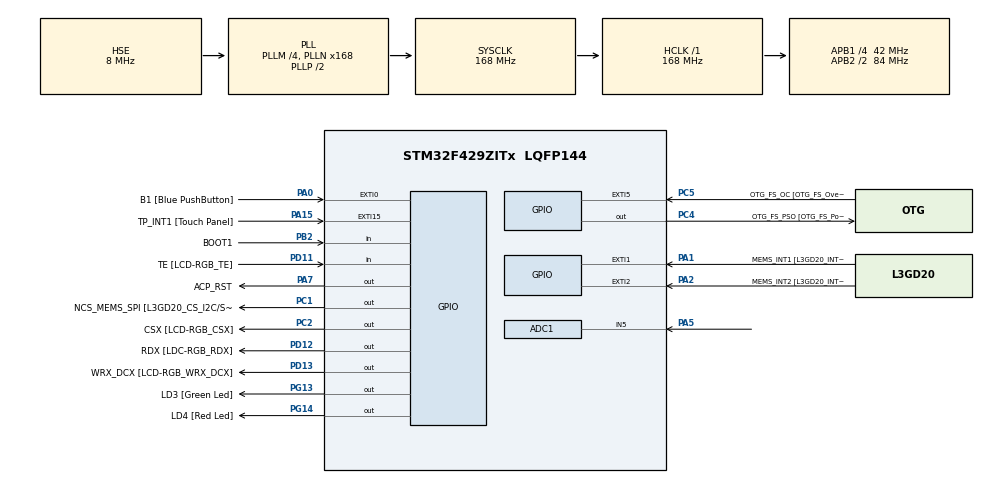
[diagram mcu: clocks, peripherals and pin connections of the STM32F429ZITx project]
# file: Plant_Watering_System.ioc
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PF5.GPIO_PuPd=GPIO_NOPULL
PD12.GPIO_Label=RDX [LDC-RGB_RDX]
PC10.GPIO_PuPd=GPIO_NOPULL
SH.FMC_A0.0=FMC_A0
PB10.GPIO_PuPd=GPIO_NOPULL
PG8.Signal=FMC_SDCLK
PG0.Signal=FMC_A10
PA3.GPIO_PuPd=GPIO_NOPULL
PE10.GPIO_PuPd=GPIO_NOPULL
PD10.GPIO_PuPd=GPIO_NOPULL
SH.FMC_D5_DA5.0=FMC_D5
PF10.GPIO_PuPd=GPIO_NOPULL
PG10.GPIO_PuPd=GPIO_NOPULL
PA6.GPIO_Mode=GPIO_MODE_AF_PP
SH.FMC_D9_DA9.0=FMC_D9
PB2/BOOT1.GPIO_Mode=GPIO_MODE_INPUT
PG13.GPIO_Mode=GPIO_MODE_OUTPUT_PP
PE13.GPIO_Mode=GPIO_MODE_AF_PP
PF13.GPIO_Mode=GPIO_MODE_AF_PP
PG15.GPIO_Label=SDNCAS
PF7.Signal=SPI5_SCK
PD13.GPIO_Mode=GPIO_MODE_OUTPUT_PP
SH.FMC_SDNWE.0=FMC_SDNWE
PA15.GPIO_ModeDefaultEXTI=GPIO_MODE_EVT_RISING
SH.FMC_D11_DA11.0=FMC_D11
PG7.GPIO_Mode=GPIO_MODE_AF_PP
PB13.GPIO_Mode=GPIO_MODE_INPUT
RCC.APB2TimFreq_Value=168000000
PC4.GPIO_Mode=GPIO_MODE_OUTPUT_PP
PB6.Signal=FMC_SDNE1
PC7.Signal=LTDC_G6
PD0.Signal=FMC_D2_DA2
PD8.Signal=FMC_D13_DA13
PE1.Signal=FMC_NBL1
PF1.GPIO_Label=A1
PC1.GPIO_PuPd=GPIO_NOPULL
PD1.GPIO_Label=D3
PB12.GPIO_Label=OTG_HS_ID
PF12.GPIO_Label=A6
PC4.GPIO_Label=OTG_FS_PSO [OTG_FS_PowerSwitchOn]
PB1.GPIO_Speed=GPIO_SPEED_FREQ_LOW
PE9.Signal=FMC_D6_DA6
PD1.GPIO_Speed=GPIO_SPEED_FREQ_VERY_HIGH
SH.FMC_A2.0=FMC_A2
PB1.GPIO_Label=R6
PG4.GPIO_Label=BA0
PD14.GPIO_PuPd=GPIO_NOPULL
PA8.Signal=I2C3_SCL
SH.FMC_D1_DA1.0=FMC_D1
PF1.GPIO_Mode=GPIO_MODE_AF_PP
PF1.GPIO_Speed=GPIO_SPEED_FREQ_VERY_HIGH
PF14.GPIO_PuPd=GPIO_NOPULL
PG0.GPIO_PuPd=GPIO_NOPULL
PE9.GPIO_Mode=GPIO_MODE_AF_PP
Mcu.Package=LQFP144
PB9.Signal=LTDC_B7
PB1.Signal=LTDC_R6
PB14.GPIO_PuPd=GPIO_NOPULL
PD12.Signal=GPIO_Output
PA10.Signal=USART1_RX
PB9.GPIO_PuPd=GPIO_NOPULL
PE12.GPIO_Label=D9
PE12.GPIO_Speed=GPIO_SPEED_FREQ_VERY_HIGH
PB5.GPIO_Speed=GPIO_SPEED_FREQ_VERY_HIGH
PE8.GPIO_Speed=GPIO_SPEED_FREQ_VERY_HIGH
PG8.GPIO_Speed=GPIO_SPEED_FREQ_VERY_HIGH
RCC.APB2CLKDivider=RCC_HCLK_DIV2
PF5.GPIO_Speed=GPIO_SPEED_FREQ_VERY_HIGH
RCC.APB1TimFreq_Value=84000000
PC14/OSC32_IN.GPIO_Label=PC14-OSC32_IN
PD3.GPIO_PuPd=GPIO_NOPULL
PF9.GPIO_PuPd=GPIO_NOPULL
PA4.GPIO_Label=VSYNC
PA8.GPIO_Speed=GPIO_SPEED_FREQ_LOW
PD15.Signal=FMC_D1_DA1
PG12.Signal=LTDC_B4
PB5.GPIO_Mode=GPIO_MODE_AF_PP
SH.FMC_A4.0=FMC_A4
PF4.GPIO_Mode=GPIO_MODE_AF_PP
PG5.Signal=FMC_A15_BA1
SH.FMC_D10_DA10.0=FMC_D10
PB6.GPIO_PuPd=GPIO_NOPULL
PD3.Signal=LTDC_G7
PC2.Signal=GPIO_Output
PF5.GPIO_Mode=GPIO_MODE_AF_PP
PG8.GPIO_PuPd=GPIO_NOPULL
PF8.GPIO_Label=SPI5_MISO [L3GD20_SDO]
PD10.Signal=FMC_D15_DA15
PC10.GPIO_Mode=GPIO_MODE_AF_PP
PB8.GPIO_Label=B6
PB10.GPIO_Mode=GPIO_MODE_AF_PP
PA8.GPIO_Label=I2C3_SCL [ACP/RF_SCL]
PE8.GPIO_Label=D5
PB1.GPIO_Mode=GPIO_MODE_AF_PP
PC5.GPIO_ModeDefaultEXTI=GPIO_MODE_EVT_RISING
PG10.GPIO_Mode=GPIO_MODE_AF_PP
PB14.Signal=USB_OTG_HS_DM
PA5.Signal=ADCx_IN5
PF10.GPIO_Mode=GPIO_MODE_AF_PP
PE1.GPIO_Label=NBL1 [SDRAM_UDQM]
PF15.GPIO_Speed=GPIO_SPEED_FREQ_VERY_HIGH
PF13.GPIO_PuPd=GPIO_NOPULL
PB13.GPIO_PuPd=GPIO_NOPULL
SH.FMC_A6.0=FMC_A6
PE14.Signal=FMC_D11_DA11
PB15.GPIO_Label=OTG_HS_DP
PF12.GPIO_Speed=GPIO_SPEED_FREQ_VERY_HIGH
PG7.GPIO_Label=DOTCLK [LCT-RGB_DOTCLK]
PF4.GPIO_Label=A4
PA1.GPIO_Label=MEMS_INT1 [L3GD20_INT1]
PC9.GPIO_PuPd=GPIO_NOPULL
PC1.GPIO_Speed=GPIO_SPEED_FREQ_LOW
PF13.Signal=FMC_A7
PA0/WKUP.GPIO_PuPd=GPIO_NOPULL
PG14.GPIO_PuPd=GPIO_NOPULL
PG1.GPIO_Speed=GPIO_SPEED_FREQ_VERY_HIGH
PC7.GPIO_Label=G6
ADC1.master=1
PB5.GPIO_PuPd=GPIO_NOPULL
ProjectManager.HeapSize=0x200
PD0.GPIO_PuPd=GPIO_NOPULL
PG12.GPIO_Speed=GPIO_SPEED_FREQ_LOW
PD8.GPIO_Speed=GPIO_SPEED_FREQ_VERY_HIGH
NVIC.PriorityGroup=NVIC_PRIORITYGROUP_0
PF0.GPIO_Label=A0
PE15.GPIO_Speed=GPIO_SPEED_FREQ_VERY_HIGH
PC15/OSC32_OUT.Signal=RCC_OSC32_OUT
PF4.Signal=FMC_A4
PD14.GPIO_Mode=GPIO_MODE_AF_PP
PG5.GPIO_Speed=GPIO_SPEED_FREQ_VERY_HIGH
Mcu.Family=STM32F4
SH.FMC_A8.0=FMC_A8
PC15/OSC32_OUT.GPIO_Label=PC15-OSC32_OUT
SH.FMC_D14_DA14.0=FMC_D14
PE11.GPIO_Label=D8
PA7.GPIO_Mode=GPIO_MODE_OUTPUT_PP
PD9.GPIO_Speed=GPIO_SPEED_FREQ_VERY_HIGH
PD0.GPIO_Label=D2
PF9.GPIO_Speed=GPIO_SPEED_FREQ_LOW
PC2.GPIO_Speed=GPIO_SPEED_FREQ_LOW
SH.FMC_A14_BA0.0=FMC_BA0
SH.FMC_A11.0=FMC_A11
PB13.GPIO_Label=VBUS_HS
PD8.GPIO_PuPd=GPIO_NOPULL
PG5.GPIO_Label=BA1
PB15.Signal=USB_OTG_HS_DP
PG11.Signal=LTDC_B3
PG15.Signal=FMC_SDNCAS
PD13.Signal=GPIO_Output
PA15.GPIO_Label=TP_INT1 [Touch Panel]
PE11.GPIO_PuPd=GPIO_NOPULL
PF11.GPIO_PuPd=GPIO_NOPULL
PB1.GPIO_PuPd=GPIO_NOPULL
PF13.GPIO_Speed=GPIO_SPEED_FREQ_VERY_HIGH
SH.FMC_NBL1.0=FMC_NBL1
PG5.GPIO_PuPd=GPIO_NOPULL
ADC1.Channel-0\#ChannelRegularConversion=ADC_CHANNEL_5
RCC.HSE_VALUE=8000000
PA4.GPIO_PuPd=GPIO_NOPULL
PF7.GPIO_Mode=GPIO_MODE_AF_PP
PE13.GPIO_PuPd=GPIO_NOPULL
PA4.GPIO_Speed=GPIO_SPEED_FREQ_LOW
PG11.GPIO_Speed=GPIO_SPEED_FREQ_LOW
PH1/OSC_OUT.GPIO_Label=PH1-OSC_OUT
PC4.GPIO_Speed=GPIO_SPEED_FREQ_LOW
PA6.GPIO_PuPd=GPIO_NOPULL
PF7.GPIO_Speed=GPIO_SPEED_FREQ_LOW
PF8.GPIO_PuPd=GPIO_NOPULL
PB2/BOOT1.GPIO_PuPd=GPIO_NOPULL
PF11.Signal=FMC_SDNRAS
PC7.GPIO_Mode=GPIO_MODE_AF_PP
PG7.GPIO_PuPd=GPIO_NOPULL
PD10.GPIO_Speed=GPIO_SPEED_FREQ_VERY_HIGH
PG4.GPIO_Mode=GPIO_MODE_AF_PP
PD6.GPIO_Mode=GPIO_MODE_AF_PP
PB12.GPIO_Mode=GPIO_MODE_AF_PP
PD13.GPIO_Label=WRX_DCX [LCD-RGB_WRX_DCX]
PA6.Signal=LTDC_G2
PB0.GPIO_Mode=GPIO_MODE_AF_PP
PB15.GPIO_PuPd=GPIO_NOPULL
PG1.GPIO_PuPd=GPIO_NOPULL
PA15.Signal=GPXTI15
PF8.Signal=SPI5_MISO
PG0.GPIO_Label=A10
PB5.GPIO_Label=SDCKE1
PD0.GPIO_Mode=GPIO_MODE_AF_PP
PG14.GPIO_Mode=GPIO_MODE_OUTPUT_PP
PG11.GPIO_Label=B3
PC5.Signal=GPXTI5
PD3.GPIO_Label=G7
PE14.GPIO_Mode=GPIO_MODE_AF_PP
PE7.Signal=FMC_D4_DA4
PD6.Signal=LTDC_B2
PF3.GPIO_Label=A3
PA1.GPIO_ModeDefaultEXTI=GPIO_MODE_EVT_RISING
PA12.GPIO_Speed=GPIO_SPEED_FREQ_LOW
PA3.Signal=LTDC_B5
PE0.GPIO_PuPd=GPIO_NOPULL
PG1.GPIO_Mode=GPIO_MODE_AF_PP
PD15.GPIO_Label=D1
PG7.Signal=LTDC_CLK
PC9.GPIO_Label=I2C3_SDA [ACP/RF_SDA]
PF10.GPIO_Speed=GPIO_SPEED_FREQ_LOW
PE14.GPIO_Label=D11
PD9.Signal=FMC_D14_DA14
PA12.GPIO_Label=R5
PD8.GPIO_Label=D13
PB0.GPIO_Speed=GPIO_SPEED_FREQ_LOW
PG8.GPIO_Label=SDCLK
PA13.Signal=SYS_JTMS-SWDIO
PB2/BOOT1.Signal=GPIO_Input
PB10.GPIO_Label=G4
PC9.GPIO_Mode=GPIO_MODE_AF_OD
SH.FMC_D13_DA13.0=FMC_D13
PA3.GPIO_Mode=GPIO_MODE_AF_PP
PG0.GPIO_Speed=GPIO_SPEED_FREQ_VERY_HIGH
PF9.GPIO_Label=SPI5_MOSI [L3GD20_SDA/SDI/SDO]
PD10.GPIO_Label=D15
PA1.Signal=GPXTI1
PA7.GPIO_PuPd=GPIO_NOPULL
PE10.GPIO_Mode=GPIO_MODE_AF_PP
board=STM32F429I-DISC1
PD13.GPIO_Speed=GPIO_SPEED_FREQ_LOW
PC7.GPIO_Speed=GPIO_SPEED_FREQ_LOW
RCC.VCOOutputFreq_Value=336000000
PA4.GPIO_Mode=GPIO_MODE_AF_PP
PF4.GPIO_Speed=GPIO_SPEED_FREQ_VERY_HIGH
PC1.GPIO_Label=NCS_MEMS_SPI [L3GD20_CS_I2C/SPI]
PE11.GPIO_Mode=GPIO_MODE_AF_PP
SH.FMC_D12_DA12.0=FMC_D12
PF15.GPIO_Label=A9
PE14.GPIO_PuPd=GPIO_NOPULL
PF1.Signal=FMC_A1
PF8.GPIO_Mode=GPIO_MODE_AF_PP
PE0.Signal=FMC_NBL0
PE7.GPIO_Label=D4
PE12.Signal=FMC_D9_DA9
PE12.GPIO_Mode=GPIO_MODE_AF_PP
RCC.48MHZClocksFreq_Value=48000000
RCC.SYSCLKFreq_VALUE=168000000
PE15.GPIO_PuPd=GPIO_NOPULL
PG4.GPIO_PuPd=GPIO_NOPULL
PD3.GPIO_Mode=GPIO_MODE_AF_PP
RCC.HSI_VALUE=16000000
PA8.GPIO_PuPd=GPIO_NOPULL
PA2.GPIO_ModeDefaultEXTI=GPIO_MODE_EVT_RISING
PH0/OSC_IN.GPIO_Label=PH0-OSC_IN
PF9.GPIO_Mode=GPIO_MODE_AF_PP
RCC.PLLQ=7
RCC.PLLM=4
RCC.PLLN=168
PG0.GPIO_Mode=GPIO_MODE_AF_PP
PB8.GPIO_Speed=GPIO_SPEED_FREQ_LOW
PD6.GPIO_Speed=GPIO_SPEED_FREQ_LOW
PG14.GPIO_Speed=GPIO_SPEED_FREQ_LOW
PB14.GPIO_Mode=GPIO_MODE_AF_PP
PB12.Signal=USB_OTG_HS_ID
PB0.GPIO_PuPd=GPIO_NOPULL
PA3.GPIO_Label=B5
PD6.GPIO_PuPd=GPIO_NOPULL
PA11.GPIO_Speed=GPIO_SPEED_FREQ_LOW
PF15.GPIO_Mode=GPIO_MODE_AF_PP
SH.FMC_D7_DA7.0=FMC_D7
PE15.GPIO_Mode=GPIO_MODE_AF_PP
PD1.GPIO_Mode=GPIO_MODE_AF_PP
PB15.GPIO_Mode=GPIO_MODE_AF_PP
PD15.GPIO_Mode=GPIO_MODE_AF_PP
PE14.GPIO_Speed=GPIO_SPEED_FREQ_VERY_HIGH
PA8.GPIO_Mode=GPIO_MODE_AF_OD
PG4.Signal=FMC_A14_BA0
PB14.GPIO_Label=OTG_HS_DM
PG6.GPIO_Label=R7
PA14.GPIO_Label=SWCLK
PE8.GPIO_PuPd=GPIO_NOPULL
PC6.GPIO_Label=HSYNC
PA6.GPIO_Label=G2
PB6.GPIO_Label=SDNE1 [SDRAM_CS]
PA3.GPIO_Speed=GPIO_SPEED_FREQ_LOW
PB13.Signal=USB_OTG_HS_VBUS
PD3.GPIO_Speed=GPIO_SPEED_FREQ_LOW
PD6.GPIO_Label=B2
PG13.Signal=GPIO_Output
RCC.SYSCLKSource=RCC_SYSCLKSOURCE_PLLCLK
PG15.GPIO_Mode=GPIO_MODE_AF_PP
PB11.GPIO_Speed=GPIO_SPEED_FREQ_LOW
SH.FMC_A15_BA1.0=FMC_BA1
PD14.GPIO_Speed=GPIO_SPEED_FREQ_VERY_HIGH
PB2/BOOT1.GPIO_Label=BOOT1
PH1/OSC_OUT.Signal=RCC_OSC_OUT
PA1.GPIO_PuPd=GPIO_NOPULL
PF10.GPIO_Label=ENABLE [LCD-RGB_ENABLE]
PF14.GPIO_Speed=GPIO_SPEED_FREQ_VERY_HIGH
PG6.GPIO_PuPd=GPIO_NOPULL
PF11.GPIO_Mode=GPIO_MODE_AF_PP
PD11.GPIO_Mode=GPIO_MODE_INPUT
PF3.Signal=FMC_A3
PE10.Signal=FMC_D7_DA7
ADC1.SamplingTime-0\#ChannelRegularConversion=ADC_SAMPLETIME_3CYCLES
PF3.GPIO_Speed=GPIO_SPEED_FREQ_VERY_HIGH
PF3.GPIO_PuPd=GPIO_NOPULL
PC6.GPIO_PuPd=GPIO_NOPULL
SH.FMC_A1.0=FMC_A1
SH.FMC_SDCLK.0=FMC_SDCLK
PC2.GPIO_Mode=GPIO_MODE_OUTPUT_PP
PG12.GPIO_PuPd=GPIO_NOPULL
PF14.Signal=FMC_A8
PA6.GPIO_Speed=GPIO_SPEED_FREQ_LOW
PB11.GPIO_Mode=GPIO_MODE_AF_PP
PA12.GPIO_PuPd=GPIO_NOPULL
PE10.GPIO_Label=D7
PD9.GPIO_PuPd=GPIO_NOPULL
PC6.GPIO_Speed=GPIO_SPEED_FREQ_LOW
SH.FMC_D3_DA3.0=FMC_D3
PG6.GPIO_Speed=GPIO_SPEED_FREQ_LOW
PE12.GPIO_PuPd=GPIO_NOPULL
PD8.GPIO_Mode=GPIO_MODE_AF_PP
ADC1.Rank-0\#ChannelRegularConversion=1
PD9.GPIO_Label=D14
PE11.GPIO_Speed=GPIO_SPEED_FREQ_VERY_HIGH
PA9.GPIO_Label=STLINK_RX [STM32F103CBT6_PA3]
PD9.GPIO_Mode=GPIO_MODE_AF_PP
PB8.GPIO_PuPd=GPIO_NOPULL
PC6.Signal=LTDC_HSYNC
PB11.GPIO_Label=G5
PD1.Signal=FMC_D3_DA3
PA11.GPIO_Label=R4
PE1.GPIO_PuPd=GPIO_NOPULL
PF14.GPIO_Label=A8
PD1.GPIO_PuPd=GPIO_NOPULL
PC0.Signal=FMC_SDNWE
RCC.APB1CLKDivider=RCC_HCLK_DIV4
PF13.GPIO_Label=A7
PG13.GPIO_Label=LD3 [Green Led]
PD0.GPIO_Speed=GPIO_SPEED_FREQ_VERY_HIGH
PG10.Signal=LTDC_G3
PE0.GPIO_Speed=GPIO_SPEED_FREQ_VERY_HIGH
PF11.GPIO_Speed=GPIO_SPEED_FREQ_VERY_HIGH
SH.FMC_A3.0=FMC_A3
PF2.GPIO_Mode=GPIO_MODE_AF_PP
PB14.GPIO_Speed=GPIO_SPEED_FREQ_LOW
SH.FMC_D15_DA15.0=FMC_D15
PA9.Signal=USART1_TX
PC7.GPIO_PuPd=GPIO_NOPULL
PE9.GPIO_Label=D6
PB10.Signal=LTDC_G4
PA7.GPIO_Speed=GPIO_SPEED_FREQ_LOW
PE7.GPIO_Speed=GPIO_SPEED_FREQ_VERY_HIGH
PE15.Signal=FMC_D12_DA12
PG11.GPIO_Mode=GPIO_MODE_AF_PP
PE8.Signal=FMC_D5_DA5
PG5.GPIO_Mode=GPIO_MODE_AF_PP
PA0/WKUP.GPIO_Label=B1 [Blue PushButton]
PC6.GPIO_Mode=GPIO_MODE_AF_PP
PG14.GPIO_Label=LD4 [Red Led]
SH.FMC_SDNCAS.0=FMC_SDNCAS
PG12.GPIO_Mode=GPIO_MODE_AF_PP
PF7.GPIO_PuPd=GPIO_NOPULL
PA4.Signal=LTDC_VSYNC
PB5.Signal=FMC_SDCKE1
PE13.GPIO_Label=D10
PD11.Signal=GPIO_Input
SH.FMC_A5.0=FMC_A5
PA11.Signal=LTDC_R4
PF9.Signal=SPI5_MOSI
SH.ADCx_IN5.0=ADC1_IN5,IN5
PC9.GPIO_Speed=GPIO_SPEED_FREQ_LOW
PF12.GPIO_PuPd=GPIO_NOPULL
PB6.GPIO_Speed=GPIO_SPEED_FREQ_VERY_HIGH
PB12.GPIO_PuPd=GPIO_NOPULL
PG6.GPIO_Mode=GPIO_MODE_AF_PP
PB0.Signal=LTDC_R3
PE0.GPIO_Mode=GPIO_MODE_AF_PP
PC1.Signal=GPIO_Output
PF3.GPIO_Mode=GPIO_MODE_AF_PP
PG10.GPIO_Label=G3
PG15.GPIO_PuPd=GPIO_NOPULL
PA2.GPIO_PuPd=GPIO_NOPULL
PE7.GPIO_PuPd=GPIO_NOPULL
RCC.CortexFreq_Value=168000000
PG6.Signal=LTDC_R7
PB10.GPIO_Speed=GPIO_SPEED_FREQ_LOW
PB6.GPIO_Mode=GPIO_MODE_AF_PP
PD15.GPIO_Speed=GPIO_SPEED_FREQ_VERY_HIGH
PC10.Signal=LTDC_R2
PF4.GPIO_PuPd=GPIO_NOPULL
SH.FMC_NBL0.0=FMC_NBL0
SH.FMC_D6_DA6.0=FMC_D6
PC0.GPIO_Label=SDNWE
PE9.GPIO_Speed=GPIO_SPEED_FREQ_VERY_HIGH
PA0/WKUP.Signal=GPXTI0
PB0.GPIO_Label=R3
PC10.GPIO_Speed=GPIO_SPEED_FREQ_LOW
PA11.GPIO_PuPd=GPIO_NOPULL
PB11.GPIO_PuPd=GPIO_NOPULL
PB11.Signal=LTDC_G5
PG8.GPIO_Mode=GPIO_MODE_AF_PP
PF2.GPIO_Speed=GPIO_SPEED_FREQ_VERY_HIGH
ProjectManager.StackSize=0x400
PD11.GPIO_PuPd=GPIO_NOPULL
SH.FMC_A7.0=FMC_A7
PA12.Signal=LTDC_R5
PE1.GPIO_Mode=GPIO_MODE_AF_PP
PH0/OSC_IN.Mode=HSE-External-Oscillator
PG11.GPIO_PuPd=GPIO_NOPULL
PD11.GPIO_Label=TE [LCD-RGB_TE]
RCC.HCLKFreq_Value=168000000
PF11.GPIO_Label=SDNRAS
PF2.GPIO_PuPd=GPIO_NOPULL
PF12.Signal=FMC_A6
SH.FMC_A10.0=FMC_A10
RCC.AHBFreq_Value=168000000
PC1.GPIO_Mode=GPIO_MODE_OUTPUT_PP
SH.FMC_D8_DA8.0=FMC_D8
PG13.GPIO_PuPd=GPIO_NOPULL
SH.FMC_D2_DA2.0=FMC_D2
PE13.Signal=FMC_D10_DA10
PF7.GPIO_Label=SPI5_SCK [L3GD20_SCL/SPC]
PG4.GPIO_Speed=GPIO_SPEED_FREQ_VERY_HIGH
PA10.GPIO_Label=STLINK_TX [STM32F103CBT6_PA2]
PA0/WKUP.GPIO_ModeDefaultEXTI=GPIO_MODE_EVT_RISING
PE10.GPIO_Speed=GPIO_SPEED_FREQ_VERY_HIGH
SH.FMC_SDNRAS.0=FMC_SDNRAS
PH1/OSC_OUT.Mode=HSE-External-Oscillator
PF12.GPIO_Mode=GPIO_MODE_AF_PP
PD12.GPIO_Mode=GPIO_MODE_OUTPUT_PP
SH.FMC_D0_DA0.0=FMC_D0
PC14/OSC32_IN.Signal=RCC_OSC32_IN
PG15.GPIO_Speed=GPIO_SPEED_FREQ_VERY_HIGH
PF15.GPIO_PuPd=GPIO_NOPULL
PA2.GPIO_Label=MEMS_INT2 [L3GD20_INT2]
PD15.GPIO_PuPd=GPIO_NOPULL
PF5.GPIO_Label=A5
SH.FMC_A9.0=FMC_A9
SH.FMC_D4_DA4.0=FMC_D4
PE8.GPIO_Mode=GPIO_MODE_AF_PP
PE0.GPIO_Label=NBL0 [SDRAM_LDQM]
PF5.Signal=FMC_A5
PB9.GPIO_Speed=GPIO_SPEED_FREQ_LOW
PG13.GPIO_Speed=GPIO_SPEED_FREQ_LOW
PF0.Signal=FMC_A0
PC0.GPIO_PuPd=GPIO_NOPULL
PC2.GPIO_Label=CSX [LCD-RGB_CSX]
PF0.GPIO_Mode=GPIO_MODE_AF_PP
RCC.PLLSourceVirtual=RCC_PLLSOURCE_HSE
PD12.GPIO_Speed=GPIO_SPEED_FREQ_LOW
PB9.GPIO_Label=B7
PC10.GPIO_Label=R2
PC4.GPIO_PuPd=GPIO_NOPULL
PG1.Signal=FMC_A11
PC4.Signal=GPIO_Output
PG10.GPIO_Speed=GPIO_SPEED_FREQ_LOW
PF0.GPIO_Speed=GPIO_SPEED_FREQ_VERY_HIGH
PD10.GPIO_Mode=GPIO_MODE_AF_PP
PC0.GPIO_Speed=GPIO_SPEED_FREQ_VERY_HIGH
PE15.GPIO_Label=D12
ProjectManager.TargetToolchain=STM32CubeIDE
PF2.Signal=FMC_A2
PE11.Signal=FMC_D8_DA8
RCC.LSE_VALUE=32768
PE7.GPIO_Mode=GPIO_MODE_AF_PP
PB12.GPIO_Speed=GPIO_SPEED_FREQ_LOW
PG14.Signal=GPIO_Output
PG1.GPIO_Label=A11
PB9.GPIO_Mode=GPIO_MODE_AF_PP
PA12.GPIO_Mode=GPIO_MODE_AF_PP
PH0/OSC_IN.Signal=RCC_OSC_IN
PG7.GPIO_Speed=GPIO_SPEED_FREQ_LOW
RCC.APB2Freq_Value=84000000
PC0.GPIO_Mode=GPIO_MODE_AF_PP
PF10.Signal=LTDC_DE
PB15.GPIO_Speed=GPIO_SPEED_FREQ_LOW
PE1.GPIO_Speed=GPIO_SPEED_FREQ_VERY_HIGH
PF1.GPIO_PuPd=GPIO_NOPULL
PD13.GPIO_PuPd=GPIO_NOPULL
PF15.Signal=FMC_A9
PD14.GPIO_Label=D0
PC2.GPIO_PuPd=GPIO_NOPULL
Mcu.Name=STM32F429ZITx
PA2.Signal=GPXTI2
PA13.GPIO_Label=SWDIO
PD14.Signal=FMC_D0_DA0
PF0.GPIO_PuPd=GPIO_NOPULL
PA7.GPIO_Label=ACP_RST
PC5.GPIO_Label=OTG_FS_OC [OTG_FS_OverCurrent]
PA14.Signal=SYS_JTCK-SWCLK
PG12.GPIO_Label=B4
ADC1.NbrOfConversionFlag=1
PF8.GPIO_Speed=GPIO_SPEED_FREQ_LOW
PA15.GPIO_PuPd=GPIO_NOPULL
PE13.GPIO_Speed=GPIO_SPEED_FREQ_VERY_HIGH
PB8.Signal=LTDC_B6
PF14.GPIO_Mode=GPIO_MODE_AF_PP
PC9.Signal=I2C3_SDA
PA11.GPIO_Mode=GPIO_MODE_AF_PP
PB8.GPIO_Mode=GPIO_MODE_AF_PP
RCC.APB1Freq_Value=42000000
PD12.GPIO_PuPd=GPIO_NOPULL
PA7.Signal=GPIO_Output
PE9.GPIO_PuPd=GPIO_NOPULL
PF2.GPIO_Label=A2

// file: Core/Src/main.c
/* USER CODE BEGIN Header */
/**
  ******************************************************************************
  * @file           : main.c
  * @brief          : Main program body
  ******************************************************************************
  * @attention
  *
  * <h2><center>&copy; Copyright (c) 2021 STMicroelectronics.
  * All rights reserved.</center></h2>
  *
  * This software component is licensed by ST under BSD 3-Clause license,
  * the "License"; You may not use this file except in compliance with the
  * License. You may obtain a copy of the License at:
  *                        opensource.org/licenses/BSD-3-Clause
  *
  ******************************************************************************
  */
/* USER CODE END Header */
#include "main.h"

ADC_HandleTypeDef hadc1;

void SystemClock_Config(void);
static void MX_GPIO_Init(void);
static void MX_ADC1_Init(void);

int main(void)
{
  /* USER CODE BEGIN 1 */
	uint32_t raw;

  /* USER CODE END 1 */

  /* MCU Configuration--------------------------------------------------------*/

  /* Reset of all peripherals, Initializes the Flash interface and the Systick. */
  HAL_Init();

  /* Configure the system clock */
  SystemClock_Config();

  /* Initialize all configured peripherals */
  MX_GPIO_Init();
  MX_ADC1_Init();

  /* Infinite loop */
  while (1)
  {

    /* USER CODE BEGIN 3 */
	  // Get ADC value
	  HAL_ADC_Start(&hadc1);
	  HAL_ADC_PollForConversion(&hadc1, HAL_MAX_DELAY);
	  raw = HAL_ADC_GetValue(&hadc1);
	  HAL_Delay(100);

  }
  /* USER CODE END 3 */
}

void SystemClock_Config(void)
{
  RCC_OscInitTypeDef RCC_OscInitStruct = {0};
  RCC_ClkInitTypeDef RCC_ClkInitStruct = {0};

  /** Configure the main internal regulator output voltage
  */
  __HAL_RCC_PWR_CLK_ENABLE();
  __HAL_PWR_VOLTAGESCALING_CONFIG(PWR_REGULATOR_VOLTAGE_SCALE1);
  /** Initializes the RCC Oscillators according to the specified parameters
  * in the RCC_OscInitTypeDef structure.
  */
  RCC_OscInitStruct.OscillatorType = RCC_OSCILLATORTYPE_HSE;
  RCC_OscInitStruct.HSEState = RCC_HSE_ON;
  RCC_OscInitStruct.PLL.PLLState = RCC_PLL_ON;
  RCC_OscInitStruct.PLL.PLLSource = RCC_PLLSOURCE_HSE;
  RCC_OscInitStruct.PLL.PLLM = 4;
  RCC_OscInitStruct.PLL.PLLN = 168;
  RCC_OscInitStruct.PLL.PLLP = RCC_PLLP_DIV2;
  RCC_OscInitStruct.PLL.PLLQ = 7;
  if (HAL_RCC_OscConfig(&RCC_OscInitStruct) != HAL_OK)
  {
    Error_Handler();
  }
  /** Initializes the CPU, AHB and APB buses clocks
  */
  RCC_ClkInitStruct.ClockType = RCC_CLOCKTYPE_HCLK|RCC_CLOCKTYPE_SYSCLK
                              |RCC_CLOCKTYPE_PCLK1|RCC_CLOCKTYPE_PCLK2;
  RCC_ClkInitStruct.SYSCLKSource = RCC_SYSCLKSOURCE_PLLCLK;
  RCC_ClkInitStruct.AHBCLKDivider = RCC_SYSCLK_DIV1;
  RCC_ClkInitStruct.APB1CLKDivider = RCC_HCLK_DIV4;
  RCC_ClkInitStruct.APB2CLKDivider = RCC_HCLK_DIV2;

  if (HAL_RCC_ClockConfig(&RCC_ClkInitStruct, FLASH_LATENCY_5) != HAL_OK)
  {
    Error_Handler();
  }
}

static void MX_ADC1_Init(void)
{

  ADC_ChannelConfTypeDef sConfig = {0};

  /** Configure the global features of the ADC (Clock, Resolution, Data Alignment and number of conversion)
  */
  hadc1.Instance = ADC1;
  hadc1.Init.ClockPrescaler = ADC_CLOCK_SYNC_PCLK_DIV4;
  hadc1.Init.Resolution = ADC_RESOLUTION_12B;
  hadc1.Init.ScanConvMode = DISABLE;
  hadc1.Init.ContinuousConvMode = DISABLE;
  hadc1.Init.DiscontinuousConvMode = DISABLE;
  hadc1.Init.ExternalTrigConvEdge = ADC_EXTERNALTRIGCONVEDGE_NONE;
  hadc1.Init.ExternalTrigConv = ADC_SOFTWARE_START;
  hadc1.Init.DataAlign = ADC_DATAALIGN_RIGHT;
  hadc1.Init.NbrOfConversion = 1;
  hadc1.Init.DMAContinuousRequests = DISABLE;
  hadc1.Init.EOCSelection = ADC_EOC_SINGLE_CONV;
  if (HAL_ADC_Init(&hadc1) != HAL_OK)
  {
    Error_Handler();
  }
  /** Configure for the selected ADC regular channel its corresponding rank in the sequencer and its sample time.
  */
  sConfig.Channel = ADC_CHANNEL_5;
  sConfig.Rank = 1;
  sConfig.SamplingTime = ADC_SAMPLETIME_3CYCLES;
  if (HAL_ADC_ConfigChannel(&hadc1, &sConfig) != HAL_OK)
  {
    Error_Handler();
  }

}

static void MX_GPIO_Init(void)
{
  GPIO_InitTypeDef GPIO_InitStruct = {0};

  /* GPIO Ports Clock Enable */
  __HAL_RCC_GPIOC_CLK_ENABLE();
  __HAL_RCC_GPIOF_CLK_ENABLE();
  __HAL_RCC_GPIOH_CLK_ENABLE();
  __HAL_RCC_GPIOA_CLK_ENABLE();
  __HAL_RCC_GPIOB_CLK_ENABLE();
  __HAL_RCC_GPIOG_CLK_ENABLE();
  __HAL_RCC_GPIOE_CLK_ENABLE();
  __HAL_RCC_GPIOD_CLK_ENABLE();

  /*Configure GPIO pin Output Level */
  HAL_GPIO_WritePin(GPIOC, NCS_MEMS_SPI_Pin|CSX_Pin|OTG_FS_PSO_Pin, GPIO_PIN_RESET);

  /*Configure GPIO pin Output Level */
  HAL_GPIO_WritePin(ACP_RST_GPIO_Port, ACP_RST_Pin, GPIO_PIN_RESET);

  /*Configure GPIO pin Output Level */
  HAL_GPIO_WritePin(GPIOD, RDX_Pin|WRX_DCX_Pin, GPIO_PIN_RESET);

  /*Configure GPIO pin Output Level */
  HAL_GPIO_WritePin(GPIOG, LD3_Pin|LD4_Pin, GPIO_PIN_RESET);

  /*Configure GPIO pins : A0_Pin A1_Pin A2_Pin A3_Pin
                           A4_Pin A5_Pin SDNRAS_Pin A6_Pin
                           A7_Pin A8_Pin A9_Pin */
  GPIO_InitStruct.Pin = A0_Pin|A1_Pin|A2_Pin|A3_Pin
                          |A4_Pin|A5_Pin|SDNRAS_Pin|A6_Pin
                          |A7_Pin|A8_Pin|A9_Pin;
  GPIO_InitStruct.Mode = GPIO_MODE_AF_PP;
  GPIO_InitStruct.Pull = GPIO_NOPULL;
  GPIO_InitStruct.Speed = GPIO_SPEED_FREQ_VERY_HIGH;
  GPIO_InitStruct.Alternate = GPIO_AF12_FMC;
  HAL_GPIO_Init(GPIOF, &GPIO_InitStruct);

  /*Configure GPIO pins : SPI5_SCK_Pin SPI5_MISO_Pin SPI5_MOSI_Pin */
  GPIO_InitStruct.Pin = SPI5_SCK_Pin|SPI5_MISO_Pin|SPI5_MOSI_Pin;
  GPIO_InitStruct.Mode = GPIO_MODE_AF_PP;
  GPIO_InitStruct.Pull = GPIO_NOPULL;
  GPIO_InitStruct.Speed = GPIO_SPEED_FREQ_LOW;
  GPIO_InitStruct.Alternate = GPIO_AF5_SPI5;
  HAL_GPIO_Init(GPIOF, &GPIO_InitStruct);

  /*Configure GPIO pin : ENABLE_Pin */
  GPIO_InitStruct.Pin = ENABLE_Pin;
  GPIO_InitStruct.Mode = GPIO_MODE_AF_PP;
  GPIO_InitStruct.Pull = GPIO_NOPULL;
  GPIO_InitStruct.Speed = GPIO_SPEED_FREQ_LOW;
  GPIO_InitStruct.Alternate = GPIO_AF14_LTDC;
  HAL_GPIO_Init(ENABLE_GPIO_Port, &GPIO_InitStruct);

  /*Configure GPIO pin : SDNWE_Pin */
  GPIO_InitStruct.Pin = SDNWE_Pin;
  GPIO_InitStruct.Mode = GPIO_MODE_AF_PP;
  GPIO_InitStruct.Pull = GPIO_NOPULL;
  GPIO_InitStruct.Speed = GPIO_SPEED_FREQ_VERY_HIGH;
  GPIO_InitStruct.Alternate = GPIO_AF12_FMC;
  HAL_GPIO_Init(SDNWE_GPIO_Port, &GPIO_InitStruct);

  /*Configure GPIO pins : NCS_MEMS_SPI_Pin CSX_Pin OTG_FS_PSO_Pin */
  GPIO_InitStruct.Pin = NCS_MEMS_SPI_Pin|CSX_Pin|OTG_FS_PSO_Pin;
  GPIO_InitStruct.Mode = GPIO_MODE_OUTPUT_PP;
  GPIO_InitStruct.Pull = GPIO_NOPULL;
  GPIO_InitStruct.Speed = GPIO_SPEED_FREQ_LOW;
  HAL_GPIO_Init(GPIOC, &GPIO_InitStruct);

  /*Configure GPIO pins : B1_Pin MEMS_INT1_Pin MEMS_INT2_Pin TP_INT1_Pin */
  GPIO_InitStruct.Pin = B1_Pin|MEMS_INT1_Pin|MEMS_INT2_Pin|TP_INT1_Pin;
  GPIO_InitStruct.Mode = GPIO_MODE_EVT_RISING;
  GPIO_InitStruct.Pull = GPIO_NOPULL;
  HAL_GPIO_Init(GPIOA, &GPIO_InitStruct);

  /*Configure GPIO pins : B5_Pin VSYNC_Pin G2_Pin R4_Pin
                           R5_Pin */
  GPIO_InitStruct.Pin = B5_Pin|VSYNC_Pin|G2_Pin|R4_Pin
                          |R5_Pin;
  GPIO_InitStruct.Mode = GPIO_MODE_AF_PP;
  GPIO_InitStruct.Pull = GPIO_NOPULL;
  GPIO_InitStruct.Speed = GPIO_SPEED_FREQ_LOW;
  GPIO_InitStruct.Alternate = GPIO_AF14_LTDC;
  HAL_GPIO_Init(GPIOA, &GPIO_InitStruct);

  /*Configure GPIO pin : ACP_RST_Pin */
  GPIO_InitStruct.Pin = ACP_RST_Pin;
  GPIO_InitStruct.Mode = GPIO_MODE_OUTPUT_PP;
  GPIO_InitStruct.Pull = GPIO_NOPULL;
  GPIO_InitStruct.Speed = GPIO_SPEED_FREQ_LOW;
  HAL_GPIO_Init(ACP_RST_GPIO_Port, &GPIO_InitStruct);

  /*Configure GPIO pin : OTG_FS_OC_Pin */
  GPIO_InitStruct.Pin = OTG_FS_OC_Pin;
  GPIO_InitStruct.Mode = GPIO_MODE_EVT_RISING;
  GPIO_InitStruct.Pull = GPIO_NOPULL;
  HAL_GPIO_Init(OTG_FS_OC_GPIO_Port, &GPIO_InitStruct);

  /*Configure GPIO pins : R3_Pin R6_Pin */
  GPIO_InitStruct.Pin = R3_Pin|R6_Pin;
  GPIO_InitStruct.Mode = GPIO_MODE_AF_PP;
  GPIO_InitStruct.Pull = GPIO_NOPULL;
  GPIO_InitStruct.Speed = GPIO_SPEED_FREQ_LOW;
  GPIO_InitStruct.Alternate = GPIO_AF9_LTDC;
  HAL_GPIO_Init(GPIOB, &GPIO_InitStruct);

  /*Configure GPIO pin : BOOT1_Pin */
  GPIO_InitStruct.Pin = BOOT1_Pin;
  GPIO_InitStruct.Mode = GPIO_MODE_INPUT;
  GPIO_InitStruct.Pull = GPIO_NOPULL;
  HAL_GPIO_Init(BOOT1_GPIO_Port, &GPIO_InitStruct);

  /*Configure GPIO pins : A10_Pin A11_Pin BA0_Pin BA1_Pin
                           SDCLK_Pin SDNCAS_Pin */
  GPIO_InitStruct.Pin = A10_Pin|A11_Pin|BA0_Pin|BA1_Pin
                          |SDCLK_Pin|SDNCAS_Pin;
  GPIO_InitStruct.Mode = GPIO_MODE_AF_PP;
  GPIO_InitStruct.Pull = GPIO_NOPULL;
  GPIO_InitStruct.Speed = GPIO_SPEED_FREQ_VERY_HIGH;
  GPIO_InitStruct.Alternate = GPIO_AF12_FMC;
  HAL_GPIO_Init(GPIOG, &GPIO_InitStruct);

  /*Configure GPIO pins : D4_Pin D5_Pin D6_Pin D7_Pin
                           D8_Pin D9_Pin D10_Pin D11_Pin
                           D12_Pin NBL0_Pin NBL1_Pin */
  GPIO_InitStruct.Pin = D4_Pin|D5_Pin|D6_Pin|D7_Pin
                          |D8_Pin|D9_Pin|D10_Pin|D11_Pin
                          |D12_Pin|NBL0_Pin|NBL1_Pin;
  GPIO_InitStruct.Mode = GPIO_MODE_AF_PP;
  GPIO_InitStruct.Pull = GPIO_NOPULL;
  GPIO_InitStruct.Speed = GPIO_SPEED_FREQ_VERY_HIGH;
  GPIO_InitStruct.Alternate = GPIO_AF12_FMC;
  HAL_GPIO_Init(GPIOE, &GPIO_InitStruct);

  /*Configure GPIO pins : G4_Pin G5_Pin B6_Pin B7_Pin */
  GPIO_InitStruct.Pin = G4_Pin|G5_Pin|B6_Pin|B7_Pin;
  GPIO_InitStruct.Mode = GPIO_MODE_AF_PP;
  GPIO_InitStruct.Pull = GPIO_NOPULL;
  GPIO_InitStruct.Speed = GPIO_SPEED_FREQ_LOW;
  GPIO_InitStruct.Alternate = GPIO_AF14_LTDC;
  HAL_GPIO_Init(GPIOB, &GPIO_InitStruct);

  /*Configure GPIO pins : OTG_HS_ID_Pin OTG_HS_DM_Pin OTG_HS_DP_Pin */
  GPIO_InitStruct.Pin = OTG_HS_ID_Pin|OTG_HS_DM_Pin|OTG_HS_DP_Pin;
  GPIO_InitStruct.Mode = GPIO_MODE_AF_PP;
  GPIO_InitStruct.Pull = GPIO_NOPULL;
  GPIO_InitStruct.Speed = GPIO_SPEED_FREQ_LOW;
  GPIO_InitStruct.Alternate = GPIO_AF12_OTG_HS_FS;
  HAL_GPIO_Init(GPIOB, &GPIO_InitStruct);

  /*Configure GPIO pin : VBUS_HS_Pin */
  GPIO_InitStruct.Pin = VBUS_HS_Pin;
  GPIO_InitStruct.Mode = GPIO_MODE_INPUT;
  GPIO_InitStruct.Pull = GPIO_NOPULL;
  HAL_GPIO_Init(VBUS_HS_GPIO_Port, &GPIO_InitStruct);

  /*Configure GPIO pins : D13_Pin D14_Pin D15_Pin D0_Pin
                           D1_Pin D2_Pin D3_Pin */
  GPIO_InitStruct.Pin = D13_Pin|D14_Pin|D15_Pin|D0_Pin
                          |D1_Pin|D2_Pin|D3_Pin;
  GPIO_InitStruct.Mode = GPIO_MODE_AF_PP;
  GPIO_InitStruct.Pull = GPIO_NOPULL;
  GPIO_InitStruct.Speed = GPIO_SPEED_FREQ_VERY_HIGH;
  GPIO_InitStruct.Alternate = GPIO_AF12_FMC;
  HAL_GPIO_Init(GPIOD, &GPIO_InitStruct);

  /*Configure GPIO pin : TE_Pin */
  GPIO_InitStruct.Pin = TE_Pin;
  GPIO_InitStruct.Mode = GPIO_MODE_INPUT;
  GPIO_InitStruct.Pull = GPIO_NOPULL;
  HAL_GPIO_Init(TE_GPIO_Port, &GPIO_InitStruct);

  /*Configure GPIO pins : RDX_Pin WRX_DCX_Pin */
  GPIO_InitStruct.Pin = RDX_Pin|WRX_DCX_Pin;
  GPIO_InitStruct.Mode = GPIO_MODE_OUTPUT_PP;
  GPIO_InitStruct.Pull = GPIO_NOPULL;
  GPIO_InitStruct.Speed = GPIO_SPEED_FREQ_LOW;
  HAL_GPIO_Init(GPIOD, &GPIO_InitStruct);

  /*Configure GPIO pins : R7_Pin DOTCLK_Pin B3_Pin */
  GPIO_InitStruct.Pin = R7_Pin|DOTCLK_Pin|B3_Pin;
  GPIO_InitStruct.Mode = GPIO_MODE_AF_PP;
  GPIO_InitStruct.Pull = GPIO_NOPULL;
  GPIO_InitStruct.Speed = GPIO_SPEED_FREQ_LOW;
  GPIO_InitStruct.Alternate = GPIO_AF14_LTDC;
  HAL_GPIO_Init(GPIOG, &GPIO_InitStruct);

  /*Configure GPIO pins : HSYNC_Pin G6_Pin R2_Pin */
  GPIO_InitStruct.Pin = HSYNC_Pin|G6_Pin|R2_Pin;
  GPIO_InitStruct.Mode = GPIO_MODE_AF_PP;
  GPIO_InitStruct.Pull = GPIO_NOPULL;
  GPIO_InitStruct.Speed = GPIO_SPEED_FREQ_LOW;
  GPIO_InitStruct.Alternate = GPIO_AF14_LTDC;
  HAL_GPIO_Init(GPIOC, &GPIO_InitStruct);

  /*Configure GPIO pin : I2C3_SDA_Pin */
  GPIO_InitStruct.Pin = I2C3_SDA_Pin;
  GPIO_InitStruct.Mode = GPIO_MODE_AF_OD;
  GPIO_InitStruct.Pull = GPIO_PULLUP;
  GPIO_InitStruct.Speed = GPIO_SPEED_FREQ_LOW;
  GPIO_InitStruct.Alternate = GPIO_AF4_I2C3;
  HAL_GPIO_Init(I2C3_SDA_GPIO_Port, &GPIO_InitStruct);

  /*Configure GPIO pin : I2C3_SCL_Pin */
  GPIO_InitStruct.Pin = I2C3_SCL_Pin;
  GPIO_InitStruct.Mode = GPIO_MODE_AF_OD;
  GPIO_InitStruct.Pull = GPIO_PULLUP;
  GPIO_InitStruct.Speed = GPIO_SPEED_FREQ_LOW;
  GPIO_InitStruct.Alternate = GPIO_AF4_I2C3;
  HAL_GPIO_Init(I2C3_SCL_GPIO_Port, &GPIO_InitStruct);

  /*Configure GPIO pins : STLINK_RX_Pin STLINK_TX_Pin */
  GPIO_InitStruct.Pin = STLINK_RX_Pin|STLINK_TX_Pin;
  GPIO_InitStruct.Mode = GPIO_MODE_AF_PP;
  GPIO_InitStruct.Pull = GPIO_NOPULL;
  GPIO_InitStruct.Speed = GPIO_SPEED_FREQ_VERY_HIGH;
  GPIO_InitStruct.Alternate = GPIO_AF7_USART1;
  HAL_GPIO_Init(GPIOA, &GPIO_InitStruct);

  /*Configure GPIO pins : G7_Pin B2_Pin */
  GPIO_InitStruct.Pin = G7_Pin|B2_Pin;
  GPIO_InitStruct.Mode = GPIO_MODE_AF_PP;
  GPIO_InitStruct.Pull = GPIO_NOPULL;
  GPIO_InitStruct.Speed = GPIO_SPEED_FREQ_LOW;
  GPIO_InitStruct.Alternate = GPIO_AF14_LTDC;
  HAL_GPIO_Init(GPIOD, &GPIO_InitStruct);

  /*Configure GPIO pins : G3_Pin B4_Pin */
  GPIO_InitStruct.Pin = G3_Pin|B4_Pin;
  GPIO_InitStruct.Mode = GPIO_MODE_AF_PP;
  GPIO_InitStruct.Pull = GPIO_NOPULL;
  GPIO_InitStruct.Speed = GPIO_SPEED_FREQ_LOW;
  GPIO_InitStruct.Alternate = GPIO_AF9_LTDC;
  HAL_GPIO_Init(GPIOG, &GPIO_InitStruct);

  /*Configure GPIO pins : LD3_Pin LD4_Pin */
  GPIO_InitStruct.Pin = LD3_Pin|LD4_Pin;
  GPIO_InitStruct.Mode = GPIO_MODE_OUTPUT_PP;
  GPIO_InitStruct.Pull = GPIO_NOPULL;
  GPIO_InitStruct.Speed = GPIO_SPEED_FREQ_LOW;
  HAL_GPIO_Init(GPIOG, &GPIO_InitStruct);

  /*Configure GPIO pins : SDCKE1_Pin SDNE1_Pin */
  GPIO_InitStruct.Pin = SDCKE1_Pin|SDNE1_Pin;
  GPIO_InitStruct.Mode = GPIO_MODE_AF_PP;
  GPIO_InitStruct.Pull = GPIO_NOPULL;
  GPIO_InitStruct.Speed = GPIO_SPEED_FREQ_VERY_HIGH;
  GPIO_InitStruct.Alternate = GPIO_AF12_FMC;
  HAL_GPIO_Init(GPIOB, &GPIO_InitStruct);

}

void Error_Handler(void)
{
  __disable_irq();
  while (1)
  {
  }
}

/************************ (C) COPYRIGHT STMicroelectronics *****END OF FILE****/
